# ATmega16HVA device description
Architecture: AVR8; Family: megaAVR
Registers are 8-bit, access not given, no defined reset value unless marked. A register's access mark holds for its fields unless they carry their own. Offsets are from the block's base; [hi:lo] are bit positions; {n}, {i} and the like mark numbered series.

## BATTERY_PROTECTION
Instances: BATTERY_PROTECTION 0x00
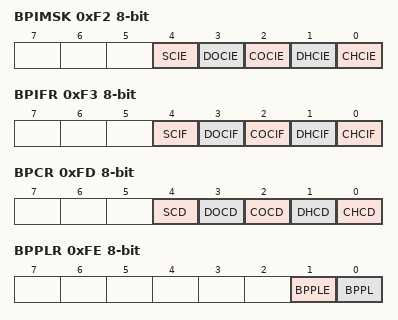
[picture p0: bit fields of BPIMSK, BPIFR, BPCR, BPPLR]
0xF2 BPIMSK — Battery Protection Interrupt Mask Register
  [4] SCIE — Short-circuit Protection Activated Interrupt Enable
  [3] DOCIE — Discharge Over-current Protection Activated Interrupt Enable
  [2] COCIE — Charge Over-current Protection Activated Interrupt Enable
  [1] DHCIE — Discharger High-current Protection Activated Interrupt
  [0] CHCIE — Charger High-current Protection Activated Interrupt
0xF3 BPIFR — Battery Protection Interrupt Flag Register
  [4] SCIF — Short-circuit Protection Activated Interrupt Flag
  [3] DOCIF — Discharge Over-current Protection Activated Interrupt Flag
  [2] COCIF — Charge Over-current Protection Activated Interrupt Flag
  [1] DHCIF — Disharge High-current Protection Activated Interrupt
  [0] CHCIF — Charge High-current Protection Activated Interrupt
0xF5 BPSCD — Battery Protection Short-Circuit Detection Level Register
0xF6 BPDOCD — Battery Protection Discharge-Over-current Detection Level Register
0xF7 BPCOCD — Battery Protection Charge-Over-current Detection Level Register
0xF8 BPDHCD — Battery Protection Discharge-High-current Detection Level Register
0xF9 BPCHCD — Battery Protection Charge-High-current Detection Level Register
0xFA BPSCTR bits used 6:0 — Battery Protection Short-current Timing Register
0xFB BPOCTR bits used 5:0 — Battery Protection Over-current Timing Register
0xFC BPHCTR bits used 5:0 — Battery Protection Short-current Timing Register
0xFD BPCR — Battery Protection Control Register
  [4] SCD — Short Circuit Protection Disabled
  [3] DOCD — Discharge Over-current Protection Disabled
  [2] COCD — Charge Over-current Protection Disabled
  [1] DHCD — Discharge High-current Protection Disable
  [0] CHCD — Charge High-current Protection Disable
0xFE BPPLR — Battery Protection Parameter Lock Register
  [1] BPPLE — Battery Protection Parameter Lock Enable
  [0] BPPL — Battery Protection Parameter Lock

## EEPROM
Instances: EEPROM 0x00
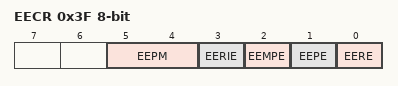
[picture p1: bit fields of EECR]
0x3F EECR — EEPROM Control Register
  [5:4] EEPM
    0=Erase and Write in one operation; 1=Erase Only; 2=Write Only
  [3] EERIE — EEProm Ready Interrupt Enable
  [2] EEMPE — EEPROM Master Write Enable
  [1] EEPE — EEPROM Write Enable
  [0] EERE — EEPROM Read Enable
0x40 EEDR — EEPROM Data Register
0x41 EEAR — EEPROM Read/Write Access

## TC1 (TC16 module) — Timer/Counter, 16-bit
Instances: TC1 0x00
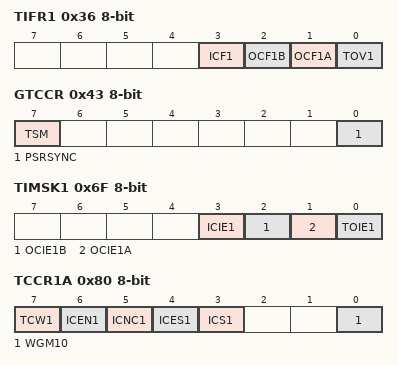
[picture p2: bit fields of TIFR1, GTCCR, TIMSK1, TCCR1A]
0x36 TIFR1 — Timer/Counter Interrupt Flag register
  [3] ICF1 — Timer/Counter 1 Input Capture Flag
  [2] OCF1B — Timer/Counter1 Output Compare Flag B
  [1] OCF1A — Timer/Counter1 Output Compare Flag A
  [0] TOV1 — Timer/Counter1 Overflow Flag
0x43 GTCCR — General Timer/Counter Control Register
  [7] TSM — Timer/Counter Synchronization Mode
  [0] PSRSYNC — Prescaler Reset
0x6F TIMSK1 — Timer/Counter Interrupt Mask Register
  [3] ICIE1 — Timer/Counter n Input Capture Interrupt Enable
  [2] OCIE1B — Timer/Counter1 Output Compare B Interrupt Enable
  [1] OCIE1A — Timer/Counter1 Output Compare A Interrupt Enable
  [0] TOIE1 — Timer/Counter1 Overflow Interrupt Enable
0x80 TCCR1A — Timer/Counter 1 Control Register A
  [7] TCW1 — Timer/Counter Width
  [6] ICEN1 — Input Capture Mode Enable
  [5] ICNC1 — Input Capture Noise Canceler
  [4] ICES1 — Input Capture Edge Select
  [3] ICS1 — Input Capture Select
  [0] WGM10 — Waveform Generation Mode
0x81 TCCR1B — Timer/Counter1 Control Register B
  [2:0] CS (bit 10 of the value upward) — Clock Select1 bis
0x84 TCNT1 16-bit — Timer Counter 1 Bytes
0x88 OCR1A — Output Compare Register 1A
0x89 OCR1B — Output Compare Register B

## TC0 (TC16 module) — Timer/Counter, 16-bit
Instances: TC0 0x00
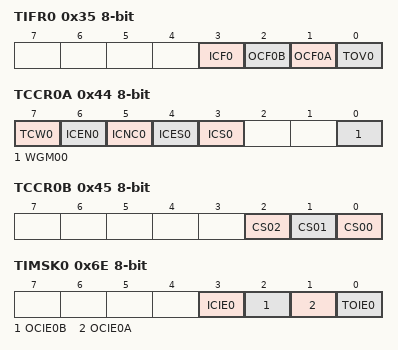
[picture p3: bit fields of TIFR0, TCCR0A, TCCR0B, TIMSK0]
0x35 TIFR0 — Timer/Counter Interrupt Flag register
  [3] ICF0 — Timer/Counter Interrupt Flag Register
  [2] OCF0B — Output Compare Flag
  [1] OCF0A — Output Compare Flag
  [0] TOV0 — Overflow Flag
0x44 TCCR0A — Timer/Counter0 Control Register
  [7] TCW0 — Timer/Counter Width
  [6] ICEN0 — Input Capture Mode Enable
  [5] ICNC0 — Input Capture Noise Canceler
  [4] ICES0 — Input Capture Edge Select
  [3] ICS0 — Input Capture Select
  [0] WGM00 — Clock Select0 bit 0
0x45 TCCR0B — Timer/Counter0 Control Register
  [2] CS02 — Clock Select0 bit 2
  [1] CS01 — Clock Select0 bit 1
  [0] CS00 — Clock Select0 bit 0
0x46 TCNT0 16-bit — Timer Counter 0 Bytes
0x48 OCR0A — Output compare Register A
0x49 OCR0B — Output compare Register B
0x6E TIMSK0 — Timer/Counter Interrupt Mask Register
  [3] ICIE0 — Timer/Counter n Input Capture Interrupt Enable
  [2] OCIE0B — Output Compare Interrupt Enable
  [1] OCIE0A — Output Compare Interrupt Enable
  [0] TOIE0 — Overflow Interrupt Enable

## COULOMB_COUNTER
Instances: COULOMB_COUNTER 0x00
{0xE0+i} CADAC{i} (i=0..3) — ADC Accumulate Current
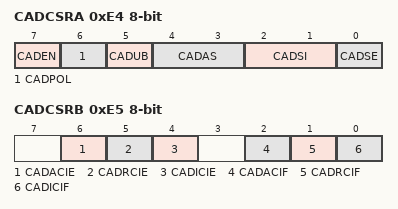
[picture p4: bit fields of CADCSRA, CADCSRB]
0xE4 CADCSRA — CC-ADC Control and Status Register A
  [7] CADEN — When the CADEN bit is cleared (zero), the CC-ADC is disabled. When the CADEN bit is set (one), the CC-ADC will continuously measure the voltage drop over the external sense resistor RSENSE. In Power-down, only the Regular Current detection is active. In Power-off, the CC-ADC is always disabled.
  [6] CADPOL
  [5] CADUB — CC_ADC Update Busy
  [4:3] CADAS — CC_ADC Accumulate Current Select Bits
  [2:1] CADSI — The CADSI bits determine the current sampling interval for the Regular Current detection in Power-down mode. The actual settings remain to be determined.
  [0] CADSE — When the CADSE bit is written to one, the ongoing CC-ADC conversion is aborted, and the CC-ADC enters Regular Current detection mode.
0xE5 CADCSRB — CC-ADC Control and Status Register B
  [6] CADACIE
  [5] CADRCIE — Regular Current Interrupt Enable
  [4] CADICIE — CAD Instantenous Current Interrupt Enable
  [2] CADACIF — CC-ADC Accumulate Current Interrupt Flag
  [1] CADRCIF — CC-ADC Accumulate Current Interrupt Flag
  [0] CADICIF — CC-ADC Instantaneous Current Interrupt Flag
0xE6 CADRC — CC-ADC Regular Current
0xE8 CADIC 16-bit — CC-ADC Instantaneous Current

## VOLTAGE_REGULATOR
Instances: VOLTAGE_REGULATOR 0x00
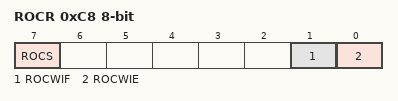
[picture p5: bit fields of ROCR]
0xC8 ROCR — Regulator Operating Condition Register
  [7] ROCS — ROC Status
  [1] ROCWIF — ROC Warning Interrupt Flag
  [0] ROCWIE — ROC Warning Interrupt Enable
